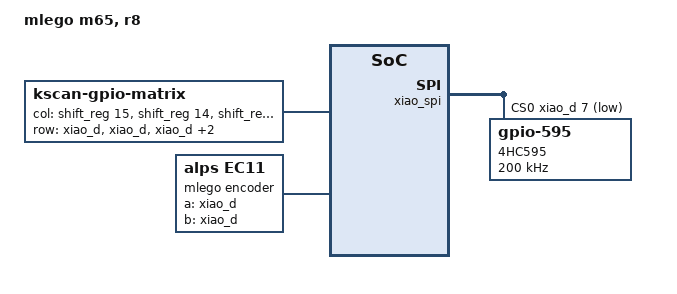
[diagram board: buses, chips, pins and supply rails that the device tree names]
/*
 * Copyright (c) 2022 alin m elena
 * SPDX-License-Identifier: MIT
 */

#include <dt-bindings/led/led.h>
#include "mlego5x13_61_r8_layout.dtsi"

/ {
   model = "mlego m65, r8";
   compatible = "mlego", "seeduino,xiao_ble";

   m65_layout: m65_layout {
        compatible = "zmk,physical-layout";
        display-name = "m65 61 default layout";
        kscan = <&kscan_m65>;
   };
   chosen {
     zmk,physical-layout = &m65_layout;
   };
   kscan_m65: kscan_m65 {
     compatible = "zmk,kscan-gpio-matrix";
     label = "kscan";
     diode-direction = "col2row";
     col-gpios = <&shift_reg 15 (GPIO_ACTIVE_HIGH)>
                 , <&shift_reg 14 (GPIO_ACTIVE_HIGH)>
                 , <&shift_reg 13 (GPIO_ACTIVE_HIGH)>
                 , <&shift_reg 12 (GPIO_ACTIVE_HIGH)>
                 , <&shift_reg 11 (GPIO_ACTIVE_HIGH)>
                 , <&shift_reg 10 (GPIO_ACTIVE_HIGH)>
                 , <&shift_reg 9 (GPIO_ACTIVE_HIGH)>
                 , <&shift_reg 8 (GPIO_ACTIVE_HIGH)>
                 , <&shift_reg 7 (GPIO_ACTIVE_HIGH)>
                 , <&shift_reg 6 (GPIO_ACTIVE_HIGH)>
                 , <&shift_reg 5 (GPIO_ACTIVE_HIGH)>
                 , <&shift_reg 4 (GPIO_ACTIVE_HIGH)>
                 , <&shift_reg 0 (GPIO_ACTIVE_HIGH)>
                 ;
     row-gpios = <&xiao_d 0(GPIO_ACTIVE_HIGH | GPIO_PULL_DOWN)>
                 ,<&xiao_d 1(GPIO_ACTIVE_HIGH | GPIO_PULL_DOWN)>
                 ,<&xiao_d 2(GPIO_ACTIVE_HIGH | GPIO_PULL_DOWN)>
                 ,<&xiao_d 3(GPIO_ACTIVE_HIGH | GPIO_PULL_DOWN)>
                 ,<&xiao_d 4(GPIO_ACTIVE_HIGH | GPIO_PULL_DOWN)>
                 ;
   };
   mlego_encoder: mlego_encoder {
     compatible = "alps,ec11";
     label = "mlego encoder";
     a-gpios = <&xiao_d 5(GPIO_ACTIVE_HIGH | GPIO_PULL_UP)>;
     b-gpios = <&xiao_d 6(GPIO_ACTIVE_HIGH | GPIO_PULL_UP)>;
     resolution = <4>;
   };

   sensors {
     compatible = "zmk,keymap-sensors";
     sensors = <&mlego_encoder>;
   };
};


&mlego_encoder { 
  status = "okay"; 
};

&xiao_spi {
  status = "okay";

  cs-gpios = <&xiao_d 7 GPIO_ACTIVE_LOW>, <&xiao_d 6 GPIO_ACTIVE_HIGH>;
  shift_reg: 595@0 {
    compatible = "zmk,gpio-595";
    status = "okay";
    gpio-controller;
    spi-max-frequency = <200000>;
    #gpio-cells = <2>;
    reg = <0>;
    label = "4HC595";
    ngpios = <16>;
  };
};

&xiao_serial { 
  status = "disabled"; 
};

